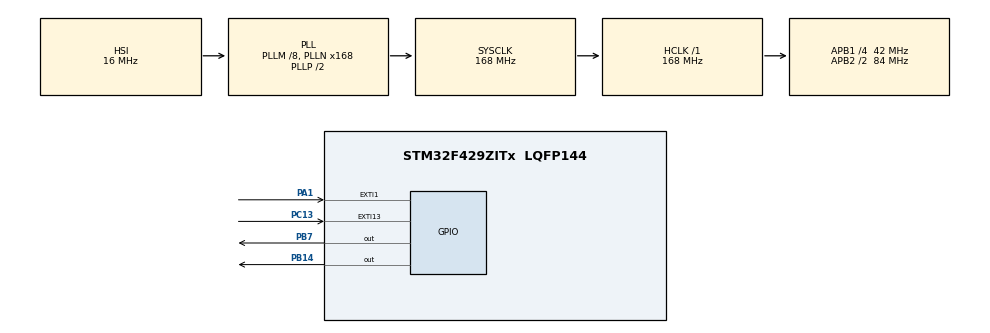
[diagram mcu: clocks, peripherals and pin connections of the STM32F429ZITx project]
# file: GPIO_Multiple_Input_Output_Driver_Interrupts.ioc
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Mcu.Family=STM32F4
Mcu.Name=STM32F429ZITx
Mcu.Package=LQFP144
NVIC.EXTI15_10_IRQn=true\:0\:0\:false\:false\:true\:true\:true\:true
NVIC.EXTI1_IRQn=true\:0\:0\:false\:false\:true\:true\:true\:true
NVIC.PriorityGroup=NVIC_PRIORITYGROUP_4
PA1.Signal=GPXTI1
PA13.Mode=Serial_Wire
PA13.Signal=SYS_JTMS-SWDIO
PA14.Mode=Serial_Wire
PA14.Signal=SYS_JTCK-SWCLK
PB14.Signal=GPIO_Output
PB7.Signal=GPIO_Output
PC13.Signal=GPXTI13
PC14/OSC32_IN.Mode=LSE-External-Oscillator
PC14/OSC32_IN.Signal=RCC_OSC32_IN
PC15/OSC32_OUT.Mode=LSE-External-Oscillator
PC15/OSC32_OUT.Signal=RCC_OSC32_OUT
ProjectManager.HeapSize=0x200
ProjectManager.StackSize=0x400
ProjectManager.TargetToolchain=STM32CubeIDE
RCC.48MHZClocksFreq_Value=48000000
RCC.AHBFreq_Value=168000000
RCC.APB1CLKDivider=RCC_HCLK_DIV4
RCC.APB1Freq_Value=42000000
RCC.APB1TimFreq_Value=84000000
RCC.APB2CLKDivider=RCC_HCLK_DIV2
RCC.APB2Freq_Value=84000000
RCC.APB2TimCLKDivider=2
RCC.APB2TimFreq_Value=168000000
RCC.CortexFreq_Value=168000000
RCC.HCLKFreq_Value=168000000
RCC.HSE_VALUE=8000000
RCC.HSI_VALUE=16000000
RCC.PLLM=8
RCC.PLLMUL=RCC_PLL_MUL9
RCC.PLLN=168
RCC.PLLQ=7
RCC.PRESCALERUSB=RCC_USBCLKSOURCE_PLL_DIV1_5
RCC.SYSCLKFreq_VALUE=168000000
RCC.SYSCLKSource=RCC_SYSCLKSOURCE_PLLCLK
RCC.SYSCLKSourceVirtual=RCC_SYSCLKSOURCE_PLLCLK
RCC.USBFreq_Value=48000000
RCC.VCOOutputFreq_Value=336000000
board=NUCLEO-F429ZI

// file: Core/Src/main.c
/* USER CODE BEGIN Header */
/**
  ******************************************************************************
  * @file           : main.c
  * @brief          : Main program body
  ******************************************************************************
  * @attention
  *
  * Copyright (c) 2023 STMicroelectronics.
  * All rights reserved.
  *
  * This software is licensed under terms that can be found in the LICENSE file
  * in the root directory of this software component.
  * If no LICENSE file comes with this software, it is provided AS-IS.
  *
  ******************************************************************************
  */
/* USER CODE END Header */
#include "main.h"

void SystemClock_Config(void);
static void MX_GPIO_Init(void);

int main(void)
{

  /* MCU Configuration--------------------------------------------------------*/

  /* Reset of all peripherals, Initializes the Flash interface and the Systick. */
  HAL_Init();

  /* Configure the system clock */
  SystemClock_Config();

  /* Initialize all configured peripherals */
  MX_GPIO_Init();

  /* Infinite loop */
  while (1)
  {

  }
}

void SystemClock_Config(void)
{
  RCC_OscInitTypeDef RCC_OscInitStruct = {0};
  RCC_ClkInitTypeDef RCC_ClkInitStruct = {0};

  /** Configure the main internal regulator output voltage
  */
  __HAL_RCC_PWR_CLK_ENABLE();
  __HAL_PWR_VOLTAGESCALING_CONFIG(PWR_REGULATOR_VOLTAGE_SCALE1);

  /** Initializes the RCC Oscillators according to the specified parameters
  * in the RCC_OscInitTypeDef structure.
  */
  RCC_OscInitStruct.OscillatorType = RCC_OSCILLATORTYPE_HSI;
  RCC_OscInitStruct.HSIState = RCC_HSI_ON;
  RCC_OscInitStruct.HSICalibrationValue = RCC_HSICALIBRATION_DEFAULT;
  RCC_OscInitStruct.PLL.PLLState = RCC_PLL_ON;
  RCC_OscInitStruct.PLL.PLLSource = RCC_PLLSOURCE_HSI;
  RCC_OscInitStruct.PLL.PLLM = 8;
  RCC_OscInitStruct.PLL.PLLN = 168;
  RCC_OscInitStruct.PLL.PLLP = RCC_PLLP_DIV2;
  RCC_OscInitStruct.PLL.PLLQ = 7;
  if (HAL_RCC_OscConfig(&RCC_OscInitStruct) != HAL_OK)
  {
    Error_Handler();
  }

  /** Initializes the CPU, AHB and APB buses clocks
  */
  RCC_ClkInitStruct.ClockType = RCC_CLOCKTYPE_HCLK|RCC_CLOCKTYPE_SYSCLK
                              |RCC_CLOCKTYPE_PCLK1|RCC_CLOCKTYPE_PCLK2;
  RCC_ClkInitStruct.SYSCLKSource = RCC_SYSCLKSOURCE_PLLCLK;
  RCC_ClkInitStruct.AHBCLKDivider = RCC_SYSCLK_DIV1;
  RCC_ClkInitStruct.APB1CLKDivider = RCC_HCLK_DIV4;
  RCC_ClkInitStruct.APB2CLKDivider = RCC_HCLK_DIV2;

  if (HAL_RCC_ClockConfig(&RCC_ClkInitStruct, FLASH_LATENCY_5) != HAL_OK)
  {
    Error_Handler();
  }
}

static void MX_GPIO_Init(void)
{
  GPIO_InitTypeDef GPIO_InitStruct = {0};

  /* GPIO Ports Clock Enable */
  __HAL_RCC_GPIOC_CLK_ENABLE();
  __HAL_RCC_GPIOA_CLK_ENABLE();
  __HAL_RCC_GPIOB_CLK_ENABLE();

  /*Configure GPIO pin Output Level */
  HAL_GPIO_WritePin(GPIOB, GPIO_PIN_14|GPIO_PIN_7, GPIO_PIN_RESET);

  /*Configure GPIO pin : PC13 */
  GPIO_InitStruct.Pin = GPIO_PIN_13;
  GPIO_InitStruct.Mode = GPIO_MODE_IT_RISING;
  GPIO_InitStruct.Pull = GPIO_NOPULL;
  HAL_GPIO_Init(GPIOC, &GPIO_InitStruct);

  /*Configure GPIO pin : PA1 */
  GPIO_InitStruct.Pin = GPIO_PIN_1;
  GPIO_InitStruct.Mode = GPIO_MODE_IT_RISING;
  GPIO_InitStruct.Pull = GPIO_NOPULL;
  HAL_GPIO_Init(GPIOA, &GPIO_InitStruct);

  /*Configure GPIO pins : PB14 PB7 */
  GPIO_InitStruct.Pin = GPIO_PIN_14|GPIO_PIN_7;
  GPIO_InitStruct.Mode = GPIO_MODE_OUTPUT_PP;
  GPIO_InitStruct.Pull = GPIO_NOPULL;
  GPIO_InitStruct.Speed = GPIO_SPEED_FREQ_LOW;
  HAL_GPIO_Init(GPIOB, &GPIO_InitStruct);

  /* EXTI interrupt init*/
  HAL_NVIC_SetPriority(EXTI1_IRQn, 0, 0);
  HAL_NVIC_EnableIRQ(EXTI1_IRQn);

  HAL_NVIC_SetPriority(EXTI15_10_IRQn, 0, 0);
  HAL_NVIC_EnableIRQ(EXTI15_10_IRQn);

}

/* USER CODE BEGIN 4 */
void HAL_GPIO_EXTI_Callback(uint16_t GPIO_Pin)
{
  /* Prevent unused argument(s) compilation warning */
  UNUSED(GPIO_Pin);

  if(GPIO_Pin==GPIO_PIN_1)
  {
	  HAL_GPIO_WritePin(GPIOB, GPIO_PIN_7, GPIO_PIN_RESET);
	  HAL_GPIO_WritePin(GPIOB, GPIO_PIN_14, GPIO_PIN_SET);
  }

  if(GPIO_Pin==GPIO_PIN_13)
   {
	  HAL_GPIO_WritePin(GPIOB, GPIO_PIN_7, GPIO_PIN_SET);
	  HAL_GPIO_WritePin(GPIOB, GPIO_PIN_14, GPIO_PIN_RESET);
    }
}
/* USER CODE END 4 */

void Error_Handler(void)
{
  __disable_irq();
  while (1)
  {
  }
}
